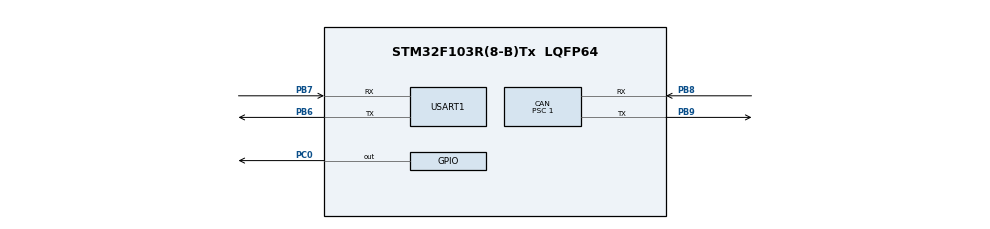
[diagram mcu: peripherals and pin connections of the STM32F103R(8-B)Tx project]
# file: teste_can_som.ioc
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CAN.BS1=CAN_BS1_3TQ
CAN.BS2=CAN_BS2_4TQ
CAN.CalculateBaudRate=1000000
CAN.CalculateTimeBit=1000
CAN.CalculateTimeQuantum=125.0
CAN.Prescaler=1
Mcu.Family=STM32F1
Mcu.Name=STM32F103R(8-B)Tx
Mcu.Package=LQFP64
NVIC.PriorityGroup=NVIC_PRIORITYGROUP_4
NVIC.USB_LP_CAN1_RX0_IRQn=true\:0\:0\:false\:false\:true\:true\:true\:true
PB6.Mode=Asynchronous
PB6.Signal=USART1_TX
PB7.Mode=Asynchronous
PB7.Signal=USART1_RX
PB8.Mode=CAN_Activate
PB8.Signal=CAN_RX
PB9.Mode=CAN_Activate
PB9.Signal=CAN_TX
PC0.Signal=GPIO_Output
ProjectManager.HeapSize=0x200
ProjectManager.StackSize=0x400
ProjectManager.TargetToolchain=STM32CubeIDE
RCC.APB1Freq_Value=8000000
RCC.APB2Freq_Value=8000000
USART1.VirtualMode=VM_ASYNC
board=custom

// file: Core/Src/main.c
#include "main.h"
#include "can.h"
#include "usart.h"
#include "gpio.h"

CAN_RxHeaderTypeDef rxHeader; //CAN Bus Transmit Header
CAN_TxHeaderTypeDef txHeader; //CAN Bus Receive Header
uint8_t canRX[8] = {0,0,0,0,0,0,0,0};  //CAN Bus Receive Buffer
CAN_FilterTypeDef canfil; //CAN Bus Filter
uint32_t canMailbox; //CAN Bus Mail box variable
uint8_t *pflag;

void SystemClock_Config(void);

int main(void)
{

  HAL_Init();

  SystemClock_Config();

  MX_GPIO_Init();
  MX_CAN_Init();
  MX_USART1_UART_Init();

  canfil.FilterBank = 0;
  canfil.FilterMode = CAN_FILTERMODE_IDMASK;
  canfil.FilterFIFOAssignment = CAN_RX_FIFO0;
  canfil.FilterIdHigh = 0;
  canfil.FilterIdLow = 0;
  canfil.FilterMaskIdHigh = 0;
  canfil.FilterMaskIdLow = 0;
  canfil.FilterScale = CAN_FILTERSCALE_32BIT;
  canfil.FilterActivation = ENABLE;
  canfil.SlaveStartFilterBank = 14;

  txHeader.DLC = 8; // Number of bites to be transmitted max- 8
  txHeader.IDE = CAN_ID_STD;
  txHeader.RTR = CAN_RTR_DATA;
  txHeader.StdId = 0x030;
  txHeader.ExtId = 0x02;
  txHeader.TransmitGlobalTime = DISABLE;

  HAL_CAN_ConfigFilter(&hcan,&canfil); //Initialize CAN Filter
  HAL_CAN_Start(&hcan); //Initialize CAN Bus
  HAL_CAN_ActivateNotification(&hcan,CAN_IT_RX_FIFO0_MSG_PENDING);// Initialize CAN Bus Rx Interrupt

  while (1)
  {

	  if (*pflag == 1){
		  	HAL_GPIO_TogglePin(GPIOC, GPIO_PIN_0);
			uint8_t csend[] = {0x01,0x02,0x03,0x04,0x05,0x06,0x07,0x08};
			HAL_CAN_AddTxMessage(&hcan,&txHeader,csend,&canMailbox);
		  	*pflag = 0;
	  }
	  HAL_Delay(1);

  }

}

void SystemClock_Config(void)
{
  RCC_OscInitTypeDef RCC_OscInitStruct = {0};
  RCC_ClkInitTypeDef RCC_ClkInitStruct = {0};

  /** Initializes the RCC Oscillators according to the specified parameters
  * in the RCC_OscInitTypeDef structure.
  */
  RCC_OscInitStruct.OscillatorType = RCC_OSCILLATORTYPE_HSI;
  RCC_OscInitStruct.HSIState = RCC_HSI_ON;
  RCC_OscInitStruct.HSICalibrationValue = RCC_HSICALIBRATION_DEFAULT;
  RCC_OscInitStruct.PLL.PLLState = RCC_PLL_NONE;
  if (HAL_RCC_OscConfig(&RCC_OscInitStruct) != HAL_OK)
  {
    Error_Handler();
  }

  /** Initializes the CPU, AHB and APB buses clocks
  */
  RCC_ClkInitStruct.ClockType = RCC_CLOCKTYPE_HCLK|RCC_CLOCKTYPE_SYSCLK
                              |RCC_CLOCKTYPE_PCLK1|RCC_CLOCKTYPE_PCLK2;
  RCC_ClkInitStruct.SYSCLKSource = RCC_SYSCLKSOURCE_HSI;
  RCC_ClkInitStruct.AHBCLKDivider = RCC_SYSCLK_DIV1;
  RCC_ClkInitStruct.APB1CLKDivider = RCC_HCLK_DIV1;
  RCC_ClkInitStruct.APB2CLKDivider = RCC_HCLK_DIV1;

  if (HAL_RCC_ClockConfig(&RCC_ClkInitStruct, FLASH_LATENCY_0) != HAL_OK)
  {
    Error_Handler();
  }
}

/* USER CODE BEGIN 4 */
void HAL_CAN_RxFifo0MsgPendingCallback(CAN_HandleTypeDef *hcan1)
{

	uint8_t flag = 0;
	HAL_CAN_GetRxMessage(&hcan, CAN_RX_FIFO0, &rxHeader, canRX);
	if (rxHeader.StdId = 0x123)
	{
		flag = 1;
	}
	pflag = &flag;
}
/* USER CODE END 4 */

void Error_Handler(void)
{
  __disable_irq();
  while (1)
  {
  }
}
